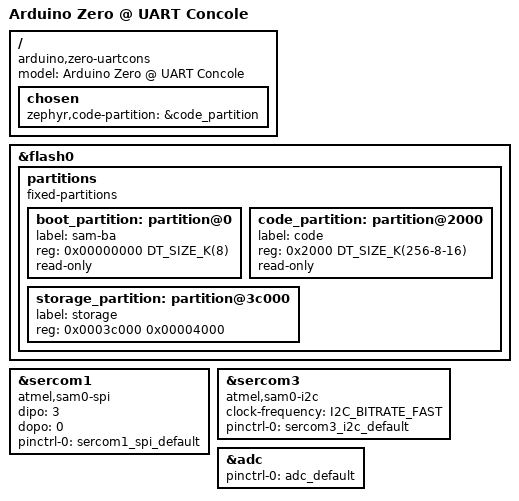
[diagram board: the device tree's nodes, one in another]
/*
 * Copyright (c) 2024 TiaC Systems
 * SPDX-License-Identifier: Apache-2.0
 */

#include <zephyr/dt-bindings/gpio/gpio.h>
#include <zephyr/dt-bindings/pwm/pwm.h>
#include <zephyr/dt-bindings/i2c/i2c.h>
#include <mem.h>

#include "arduino_zero-pinctrl.dtsi"
#include "arduino_r3_connector.dtsi"

/ {
	model = "Arduino Zero @ UART Concole";
	compatible = "arduino,zero-uartcons", "arduino,zero",
		     "atmel,samd21g18a", "atmel,samd21";

	chosen {
		zephyr,code-partition = &code_partition;	/* missing upstream */
	};
};

&flash0 {
	partitions {
		compatible = "fixed-partitions";
		#address-cells = <1>;
		#size-cells = <1>;

		boot_partition: partition@0 {			/* missing upstream */
			label = "sam-ba";
			reg = <0x00000000 DT_SIZE_K(8)>;
			read-only;
		};

		code_partition: partition@2000 {		/* missing upstream */
			label = "code";
			reg = <0x2000 DT_SIZE_K(256-8-16)>;
			read-only;
		};

		/*
		 * The final 16 KiB is reserved for the application.
		 * Storage partition will be used by FCB/LittleFS/NVS
		 * if enabled.
		 */
		storage_partition: partition@3c000 {
			label = "storage";
			reg = <0x0003c000 0x00004000>;
		};
	};
};

&sercom1 {							/* missing upstream */
	status = "okay";
	compatible = "atmel,sam0-spi";
	dipo = <3>;
	dopo = <0>;
	#address-cells = <1>;
	#size-cells = <0>;

	// either: cs-gpios = <&arduino_header 16 GPIO_ACTIVE_LOW>;	/* D10 */
	//     or: cs-gpios = <&porta 18 GPIO_ACTIVE_LOW>;
	//     or: pinctrl-0 = <&sercom1_spi_hwss>;

	pinctrl-0 = <&sercom1_spi_default>;
	pinctrl-names = "default";
};

&sercom3 {							/* missing upstream */
	status = "okay";
	compatible = "atmel,sam0-i2c";
	clock-frequency = <I2C_BITRATE_FAST>;
	#address-cells = <1>;
	#size-cells = <0>;

	pinctrl-0 = <&sercom3_i2c_default>;
	pinctrl-names = "default";
};

&adc {								/* missing upstream */
	status = "okay";

	pinctrl-0 = <&adc_default>;
	pinctrl-names = "default";
};
